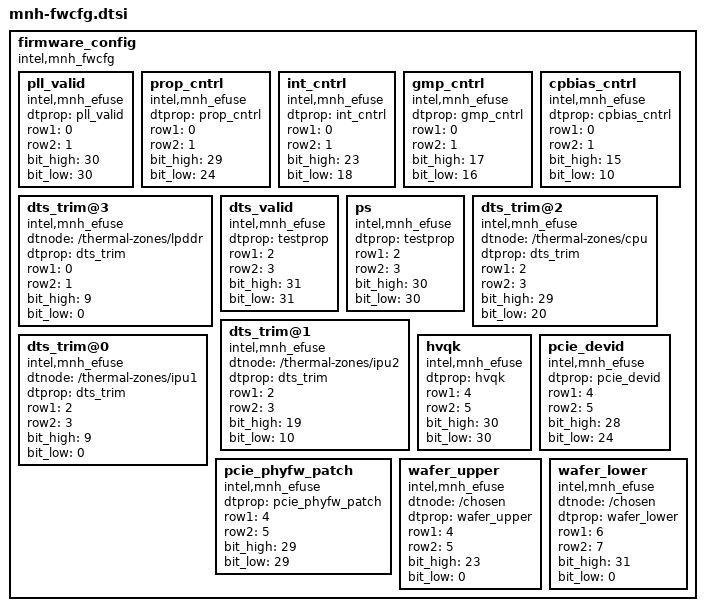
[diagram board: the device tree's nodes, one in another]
firmware_config {
        compatible = "intel,mnh_fwcfg";
        status = "okay";
	/* dtnode and dtprop are where to put the value
	extracted from the efuse data */
        pll_valid {
                compatible = "intel,mnh_efuse";
	        //dtnode = "/testnode@0";
                dtprop = "pll_valid";
		row1    = <0>;
		row2    = <1>;
                bit_high= <30>;
                bit_low = <30>;
        };
        prop_cntrl {
                compatible = "intel,mnh_efuse";
                //dtnode = "/testnode@0";
                dtprop = "prop_cntrl";
                row1    = <0>;
                row2    = <1>;
                bit_high= <29>;
                bit_low = <24>;
        };
        int_cntrl {
                compatible = "intel,mnh_efuse";
                //dtnode = "/testnode@0";
                dtprop = "int_cntrl";
                row1    = <0>;
                row2    = <1>;
                bit_high= <23>;
                bit_low = <18>;
        };
        gmp_cntrl {
                compatible = "intel,mnh_efuse";
                //dtnode = "/testnode@0";
                dtprop = "gmp_cntrl";
                row1    = <0>;
                row2    = <1>;
                bit_high= <17>;
                bit_low = <16>;
        };
        cpbias_cntrl {
                compatible = "intel,mnh_efuse";
                //dtnode = "/testnode@0";
                dtprop = "cpbias_cntrl";
                row1    = <0>;
                row2    = <1>;
                bit_high= <15>;
                bit_low = <10>;
        };
        dts_trim@3 {
                compatible = "intel,mnh_efuse";
                dtnode = "/thermal-zones/lpddr";
                dtprop = "dts_trim";
                row1    = <0>;
                row2    = <1>;
                bit_high= <9>;
                bit_low = <0>;
        };
        dts_valid {
                compatible = "intel,mnh_efuse";
                //dtnode = "/testnode@0";
                dtprop = "testprop";
                row1    = <2>;
                row2    = <3>;
                bit_high= <31>;
                bit_low = <31>;
        };
        ps {
                compatible = "intel,mnh_efuse";
                //dtnode = "/testnode@0";
                dtprop = "testprop";
                row1    = <2>;
                row2    = <3>;
                bit_high= <30>;
                bit_low = <30>;
        };
        dts_trim@2 {
                compatible = "intel,mnh_efuse";
                dtnode = "/thermal-zones/cpu";
                dtprop = "dts_trim";
                row1    = <2>;
                row2    = <3>;
                bit_high= <29>;
                bit_low = <20>;
        };
        dts_trim@1 {
                compatible = "intel,mnh_efuse";
                dtnode = "/thermal-zones/ipu2";
                dtprop = "dts_trim";
                row1    = <2>;
                row2    = <3>;
                bit_high= <19>;
                bit_low = <10>;
        };
        dts_trim@0 {
                compatible = "intel,mnh_efuse";
                dtnode = "/thermal-zones/ipu1";
                dtprop = "dts_trim";
                row1    = <2>;
                row2    = <3>;
                bit_high= <9>;
                bit_low = <0>;
        };
        hvqk {
                compatible = "intel,mnh_efuse";
                //dtnode = "/testnode@0";
                dtprop = "hvqk";
                row1    = <4>;
                row2    = <5>;
                bit_high= <30>;
                bit_low = <30>;
        };
        pcie_phyfw_patch {
                compatible = "intel,mnh_efuse";
                //dtnode = "/testnode@0";
                dtprop = "pcie_phyfw_patch";
                row1    = <4>;
                row2    = <5>;
                bit_high= <29>;
                bit_low = <29>;
        };
        pcie_devid {
                compatible = "intel,mnh_efuse";
                //dtnode = "/testnode@0";
                dtprop = "pcie_devid";
                row1    = <4>;
                row2    = <5>;
                bit_high= <28>;
                bit_low = <24>;
        };
        wafer_upper {
                compatible = "intel,mnh_efuse";
                dtnode = "/chosen";
                dtprop = "wafer_upper";
                row1    = <4>;
                row2    = <5>;
                bit_high= <23>;
                bit_low = <0>;
        };
        wafer_lower {
                compatible = "intel,mnh_efuse";
                dtnode = "/chosen";
                dtprop = "wafer_lower";
                row1    = <6>;
                row2    = <7>;
                bit_high= <31>;
                bit_low = <0>;
        };
};

